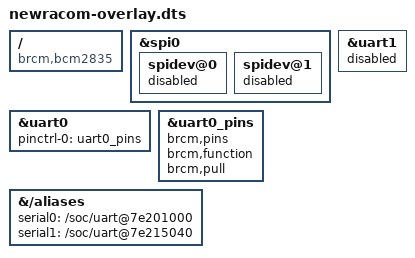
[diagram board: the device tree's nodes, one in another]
/*
 * Device Tree overlay for Newracom
 */

/dts-v1/;
/plugin/;

/* this includes disabling SPI and pi3-disable-bt overlay
*/

/{
        compatible = "brcm,bcm2835", "brcm,bcm2708", "brcm,bcm2709";

        fragment@0 {
                target = <&spi0>;
                __overlay__ {
                        status = "okay";

                        spidev@0{
                                status = "disabled";
                        };

                        spidev@1{
                                status = "disabled";
                        };
                };
        };

        fragment@1 {
                target = <&uart1>;
                __overlay__ {
                        status = "disabled";
                };
        };

        fragment@2 {
                target = <&uart0>;
                __overlay__ {
                        pinctrl-names = "default";
                        pinctrl-0 = <&uart0_pins>;
                        status = "okay";
                };
        };

        fragment@3 {
                target = <&uart0_pins>;
                __overlay__ {
                        brcm,pins;
                        brcm,function;
                        brcm,pull;
                };
        };

        fragment@4 {
                target-path = "/aliases";
                __overlay__ {
                        serial0 = "/soc/uart@7e201000";
                        serial1 = "/soc/uart@7e215040";
                };
        };
};
